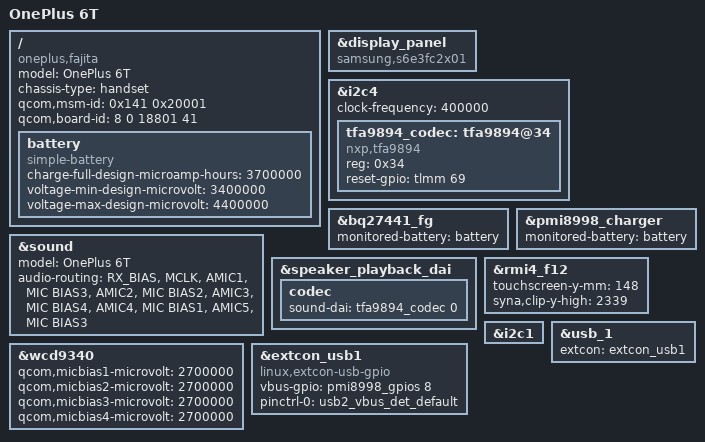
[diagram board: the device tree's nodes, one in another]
// SPDX-License-Identifier: GPL-2.0
/*
 * SDM845 OnePlus 6T (fajita) device tree.
 *
 * Copyright (c) 2020, The Linux Foundation. All rights reserved.
 */

#include "sdm845-oneplus-common.dtsi"

/ {
	model = "OnePlus 6T";
	compatible = "oneplus,fajita", "qcom,sdm845";
	chassis-type = "handset";
	qcom,msm-id = <0x141 0x20001>;
	qcom,board-id = <8 0 18801 41>;

	battery: battery {
		compatible = "simple-battery";

		charge-full-design-microamp-hours = <3700000>;
		voltage-min-design-microvolt = <3400000>;
		voltage-max-design-microvolt = <4400000>;
	};
};

&display_panel {
	status = "okay";

	compatible = "samsung,s6e3fc2x01";
};
/*
&ext_5v_boost {
	status = "ok";
};
*/
&i2c4 {
	status = "okay";
	clock-frequency = <400000>;

	tfa9894_codec: tfa9894@34 {
		#sound-dai-cells = <1>;
		compatible = "nxp,tfa9894";
		reg = <0x34>;
		reset-gpio = <&tlmm 69 0>;
	};

};

&bq27441_fg {
	monitored-battery = <&battery>;
};

&sound {
	model = "OnePlus 6T";
	audio-routing = "RX_BIAS", "MCLK",
			"AMIC1", "MIC BIAS3",
			"AMIC2", "MIC BIAS2",
			"AMIC3", "MIC BIAS4",
			"AMIC4", "MIC BIAS1",
			"AMIC5", "MIC BIAS3";
};

&pmi8998_charger {
	monitored-battery = <&battery>;
};

&speaker_playback_dai {
	codec {
		sound-dai = <&tfa9894_codec 0>;
	};
};

&rmi4_f12 {
	touchscreen-y-mm = <148>;
	syna,clip-y-high = <2339>;
};

&i2c1 {
/*	status = "ok";
	clock-frequency = <100000>;

	pn5xx@28 {
		compatible = "nxp,pn544";
		reg = <0x28>;
		nxp,pn544-irq = <&tlmm 63 0x00>;
		nxp,pn544-ven = <&tlmm 12 0x00>;
		nxp,pn544-fw-dwnld = <&tlmm 62 0x00>;
		nxp,pn544-clk-gpio = <&pm8998_gpios 21 0x00>;
		nxp,pn544-ese-pwr = <&tlmm 116 0x00>;
		nfc_voltage_s4-supply = <&vreg_s4a_1p8>;
		nxp,pn544-wake-up = <&tlmm 129 0x00>;
		interrupt-parent = <&tlmm>;
		qcom,clk-src = "BBCLK3";
		interrupts = <63 0>;
		interrupt-names = "nfc_irq";
		pinctrl-names = "nfc_active", "nfc_suspend";
		pinctrl-0 = <&nfc_int_active
			     &nfc_enable_active
			     &nfc_clk_default>;
		pinctrl-1 = <&nfc_int_suspend &nfc_enable_suspend>;
		clocks = <&rpmhcc RPMH_CXO_CLK>;
		clock-names = "ref_clk";
	};
*/
};

&wcd9340 {
	qcom,micbias1-microvolt = <2700000>;
	qcom,micbias2-microvolt = <2700000>;
	qcom,micbias3-microvolt = <2700000>;
	qcom,micbias4-microvolt = <2700000>;
};

&extcon_usb1 {
		compatible = "linux,extcon-usb-gpio";
		vbus-gpio = <&pmi8998_gpios 8 GPIO_ACTIVE_HIGH>;

		pinctrl-names = "default";
		pinctrl-0 = <&usb2_vbus_det_default>;
};



&usb_1 {
	extcon = <&extcon_usb1>;
};

